AUTOSAR XML (schema 4-2-2)
package /ComponentTypes
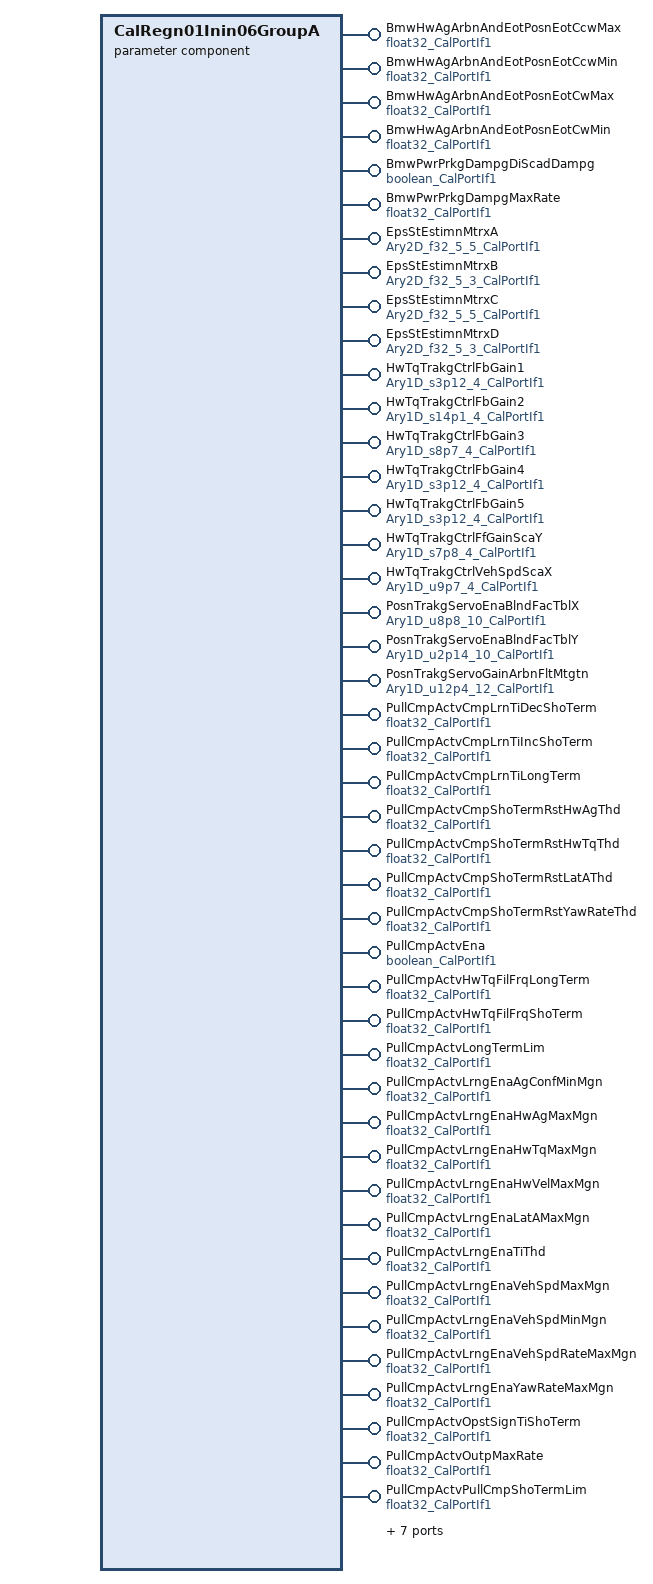
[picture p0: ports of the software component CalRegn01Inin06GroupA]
  parameter sw component type CalRegn01Inin06GroupA
    51 x provide port:
      BmwHwAgArbnAndEotPosnEotCcwMax: parameter-provide-com-spec{init-value=-360, parameter=Val}, provided-interface=float32_CalPortIf1
      BmwHwAgArbnAndEotPosnEotCcwMin: parameter-provide-com-spec{init-value=-900, parameter=Val}, provided-interface=float32_CalPortIf1
      BmwHwAgArbnAndEotPosnEotCwMax: parameter-provide-com-spec{init-value=900, parameter=Val}, provided-interface=float32_CalPortIf1
      BmwHwAgArbnAndEotPosnEotCwMin: parameter-provide-com-spec{init-value=360, parameter=Val}, provided-interface=float32_CalPortIf1
      BmwPwrPrkgDampgDiScadDampg: parameter-provide-com-spec{init-value=1, parameter=Logl}, provided-interface=boolean_CalPortIf1
      BmwPwrPrkgDampgMaxRate: parameter-provide-com-spec{init-value=1, parameter=Val}, provided-interface=float32_CalPortIf1
      EpsStEstimnMtrxA: parameter-provide-com-spec{init-value=[[1, 0, 0, 0, 0], [0, 1, 0, 0, 0], [0, 0, 1, 0, 0], [0, 0, 0, 1, 0], [0, 0, 0, 0, 1]], parameter=Ary2D}, provided-interface=Ary2D_f32_5_5_CalPortIf1
      EpsStEstimnMtrxB: parameter-provide-com-spec{init-value=5 x [0, 0, 0], parameter=Ary2D}, provided-interface=Ary2D_f32_5_3_CalPortIf1
      EpsStEstimnMtrxC: parameter-provide-com-spec{init-value=[[1, 0, 0, 0, 0], [0, 1, 0, 0, 0], [0, 0, 1, 0, 0], [0, 0, 0, 1, 0], [0, 0, 0, 0, 1]], parameter=Ary2D}, provided-interface=Ary2D_f32_5_5_CalPortIf1
      EpsStEstimnMtrxD: parameter-provide-com-spec{init-value=5 x [0, 0, 0], parameter=Ary2D}, provided-interface=Ary2D_f32_5_3_CalPortIf1
      HwTqTrakgCtrlFbGain1: parameter-provide-com-spec{init-value=[0, 0, 0, 0], parameter=Ary1D}, provided-interface=Ary1D_s3p12_4_CalPortIf1
      HwTqTrakgCtrlFbGain2: parameter-provide-com-spec{init-value=[0, 0, 0, 0], parameter=Ary1D}, provided-interface=Ary1D_s14p1_4_CalPortIf1
      HwTqTrakgCtrlFbGain3: parameter-provide-com-spec{init-value=[0, 0, 0, 0], parameter=Ary1D}, provided-interface=Ary1D_s8p7_4_CalPortIf1
      HwTqTrakgCtrlFbGain4: parameter-provide-com-spec{init-value=[0, 0, 0, 0], parameter=Ary1D}, provided-interface=Ary1D_s3p12_4_CalPortIf1
      HwTqTrakgCtrlFbGain5: parameter-provide-com-spec{init-value=[0, 0, 0, 0], parameter=Ary1D}, provided-interface=Ary1D_s3p12_4_CalPortIf1
      HwTqTrakgCtrlFfGainScaY: parameter-provide-com-spec{init-value=[0, 0, 0, 0], parameter=Ary1D}, provided-interface=Ary1D_s7p8_4_CalPortIf1
      HwTqTrakgCtrlVehSpdScaX: parameter-provide-com-spec{init-value=[0, 1280, 2560, 25600], parameter=Ary1D}, provided-interface=Ary1D_u9p7_4_CalPortIf1
      PosnTrakgServoEnaBlndFacTblX: parameter-provide-com-spec{init-value=[0, 26, 51, 77, 128, 256, 512, 768, 1024, 2560], parameter=Ary1D}, provided-interface=Ary1D_u8p8_10_CalPortIf1
      PosnTrakgServoEnaBlndFacTblY: parameter-provide-com-spec{init-value=[0, 164, 328, 819, 1638, 3277, 8192, 11469, 16384, 16384], parameter=Ary1D}, provided-interface=Ary1D_u2p14_10_CalPortIf1
      PosnTrakgServoGainArbnFltMtgtn: parameter-provide-com-spec{init-value=[960, 960, 800, 640, 480, 320, 320, 160, 160, 160, 160, 160], parameter=Ary1D}, provided-interface=Ary1D_u12p4_12_CalPortIf1
      PullCmpActvCmpLrnTiDecShoTerm: parameter-provide-com-spec{init-value=45, parameter=Val}, provided-interface=float32_CalPortIf1
      PullCmpActvCmpLrnTiIncShoTerm: parameter-provide-com-spec{init-value=45, parameter=Val}, provided-interface=float32_CalPortIf1
      PullCmpActvCmpLrnTiLongTerm: parameter-provide-com-spec{init-value=45, parameter=Val}, provided-interface=float32_CalPortIf1
      PullCmpActvCmpShoTermRstHwAgThd: parameter-provide-com-spec{init-value=45, parameter=Val}, provided-interface=float32_CalPortIf1
      PullCmpActvCmpShoTermRstHwTqThd: parameter-provide-com-spec{init-value=3, parameter=Val}, provided-interface=float32_CalPortIf1
      PullCmpActvCmpShoTermRstLatAThd: parameter-provide-com-spec{init-value=1, parameter=Val}, provided-interface=float32_CalPortIf1
      PullCmpActvCmpShoTermRstYawRateThd: parameter-provide-com-spec{init-value=1, parameter=Val}, provided-interface=float32_CalPortIf1
      PullCmpActvEna: parameter-provide-com-spec{init-value=1, parameter=Logl}, provided-interface=boolean_CalPortIf1
      PullCmpActvHwTqFilFrqLongTerm: parameter-provide-com-spec{init-value=0.5, parameter=Val}, provided-interface=float32_CalPortIf1
      PullCmpActvHwTqFilFrqShoTerm: parameter-provide-com-spec{init-value=0.5, parameter=Val}, provided-interface=float32_CalPortIf1
      PullCmpActvLongTermLim: parameter-provide-com-spec{init-value=0.5, parameter=Val}, provided-interface=float32_CalPortIf1
      PullCmpActvLrngEnaAgConfMinMgn: parameter-provide-com-spec{init-value=1, parameter=Val}, provided-interface=float32_CalPortIf1
      PullCmpActvLrngEnaHwAgMaxMgn: parameter-provide-com-spec{init-value=45, parameter=Val}, provided-interface=float32_CalPortIf1
      PullCmpActvLrngEnaHwTqMaxMgn: parameter-provide-com-spec{init-value=2.8, parameter=Val}, provided-interface=float32_CalPortIf1
      PullCmpActvLrngEnaHwVelMaxMgn: parameter-provide-com-spec{init-value=10, parameter=Val}, provided-interface=float32_CalPortIf1
      PullCmpActvLrngEnaLatAMaxMgn: parameter-provide-com-spec{init-value=0.5, parameter=Val}, provided-interface=float32_CalPortIf1
      PullCmpActvLrngEnaTiThd: parameter-provide-com-spec{init-value=2, parameter=Val}, provided-interface=float32_CalPortIf1
      PullCmpActvLrngEnaVehSpdMaxMgn: parameter-provide-com-spec{init-value=160, parameter=Val}, provided-interface=float32_CalPortIf1
      PullCmpActvLrngEnaVehSpdMinMgn: parameter-provide-com-spec{init-value=60, parameter=Val}, provided-interface=float32_CalPortIf1
      PullCmpActvLrngEnaVehSpdRateMaxMgn: parameter-provide-com-spec{init-value=1, parameter=Val}, provided-interface=float32_CalPortIf1
      PullCmpActvLrngEnaYawRateMaxMgn: parameter-provide-com-spec{init-value=1, parameter=Val}, provided-interface=float32_CalPortIf1
      PullCmpActvOpstSignTiShoTerm: parameter-provide-com-spec{init-value=0.1, parameter=Val}, provided-interface=float32_CalPortIf1
      PullCmpActvOutpMaxRate: parameter-provide-com-spec{init-value=100, parameter=Val}, provided-interface=float32_CalPortIf1
      PullCmpActvPullCmpShoTermLim: parameter-provide-com-spec{init-value=1, parameter=Val}, provided-interface=float32_CalPortIf1
      PullCmpActvPullCmpTotLim: parameter-provide-com-spec{init-value=0, parameter=Val}, provided-interface=float32_CalPortIf1
      PullCmpActvPullErrLimLongTerm: parameter-provide-com-spec{init-value=3, parameter=Val}, provided-interface=float32_CalPortIf1
      PullCmpActvPullErrMgnThd: parameter-provide-com-spec{init-value=0.25, parameter=Val}, provided-interface=float32_CalPortIf1
      PullCmpActvPullErrShoTermLim: parameter-provide-com-spec{init-value=3, parameter=Val}, provided-interface=float32_CalPortIf1
      PullCmpActvShoTermRampTi: parameter-provide-com-spec{init-value=1, parameter=Val}, provided-interface=float32_CalPortIf1
      PullCmpActvVehSpdScaTblX: parameter-provide-com-spec{init-value=[0, 3840, 7680, 11520], parameter=Ary1D}, provided-interface=Ary1D_u9p7_4_CalPortIf1
      PullCmpActvVehSpdScaTblY: parameter-provide-com-spec{init-value=[0, 4096, 16384, 16384], parameter=Ary1D}, provided-interface=Ary1D_u2p14_4_CalPortIf1
